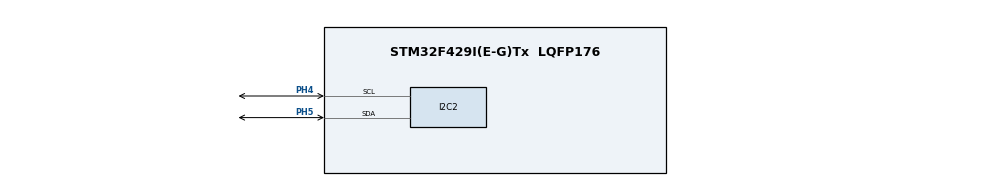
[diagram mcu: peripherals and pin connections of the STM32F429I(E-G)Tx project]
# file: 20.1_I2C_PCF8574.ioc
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I2C2.I2C_Mode=I2C_Fast
Mcu.Family=STM32F4
Mcu.Name=STM32F429I(E-G)Tx
Mcu.Package=LQFP176
NVIC.PriorityGroup=NVIC_PRIORITYGROUP_4
PA13.Mode=Trace_Asynchronous_SW
PA13.Signal=SYS_JTMS-SWDIO
PA14.Mode=Trace_Asynchronous_SW
PA14.Signal=SYS_JTCK-SWCLK
PB3.Mode=Trace_Asynchronous_SW
PB3.Signal=SYS_JTDO-SWO
PC14/OSC32_IN.Mode=LSE-External-Oscillator
PC14/OSC32_IN.Signal=RCC_OSC32_IN
PC15/OSC32_OUT.Mode=LSE-External-Oscillator
PC15/OSC32_OUT.Signal=RCC_OSC32_OUT
PH0/OSC_IN.Mode=HSE-External-Oscillator
PH0/OSC_IN.Signal=RCC_OSC_IN
PH1/OSC_OUT.Mode=HSE-External-Oscillator
PH1/OSC_OUT.Signal=RCC_OSC_OUT
PH4.Mode=I2C
PH4.Signal=I2C2_SCL
PH5.Mode=I2C
PH5.Signal=I2C2_SDA
ProjectManager.HeapSize=0x200
ProjectManager.StackSize=0x400
ProjectManager.TargetToolchain=STM32CubeIDE
RCC.48MHZClocksFreq_Value=90000000
RCC.AHBFreq_Value=180000000
RCC.APB1CLKDivider=RCC_HCLK_DIV4
RCC.APB1Freq_Value=45000000
RCC.APB1TimFreq_Value=90000000
RCC.APB2CLKDivider=RCC_HCLK_DIV2
RCC.APB2Freq_Value=90000000
RCC.APB2TimFreq_Value=180000000
RCC.CortexFreq_Value=180000000
RCC.HCLKFreq_Value=180000000
RCC.HSE_VALUE=25000000
RCC.HSI_VALUE=16000000
RCC.PLLM=15
RCC.PLLN=216
RCC.PLLSourceVirtual=RCC_PLLSOURCE_HSE
RCC.SYSCLKFreq_VALUE=180000000
RCC.SYSCLKSource=RCC_SYSCLKSOURCE_PLLCLK
RCC.VCOOutputFreq_Value=360000000
board=custom

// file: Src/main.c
/* USER CODE BEGIN Header */
/**
 ******************************************************************************
 * @file           : main.c
 * @brief          : Main program body
 ******************************************************************************
 * @attention
 *
 * <h2><center>&copy; Copyright (c) 2019 STMicroelectronics.
 * All rights reserved.</center></h2>
 *
 * This software component is licensed by ST under BSD 3-Clause license,
 * the "License"; You may not use this file except in compliance with the
 * License. You may obtain a copy of the License at:
 *                        opensource.org/licenses/BSD-3-Clause
 *
 ******************************************************************************
 */
/* USER CODE END Header */

#include "main.h"
#include "i2c.h"
#include "gpio.h"

/* USER CODE BEGIN Includes */
#include <stdio.h>
#include "PCF8574.h"
/* USER CODE END Includes */

/* USER CODE BEGIN PD */
#define EEPROM_ADDRESS		0X40
//#define EEPROM_ADDRESS		0xA0
/* USER CODE END PD */

/* USER CODE BEGIN PV */
uint8_t wirte_singnal = 99;
uint8_t read_singnal = 0;

uint8_t sinagl_buf = 0;
/* USER CODE END PV */

void SystemClock_Config (void);

int main (void)
{

    /* MCU Configuration--------------------------------------------------------*/

    /* Reset of all peripherals, Initializes the Flash interface and the Systick. */
    HAL_Init ();

    /* Configure the system clock */
    SystemClock_Config ();

    /* Initialize all configured peripherals */
    MX_GPIO_Init ();
    MX_I2C2_Init ();
    /* USER CODE BEGIN 2 */
    printf ("Start\r\n");
    while (PCF8574_Init ());
    printf ("Init done\r\n");

    int data = 0x5f;
    /* USER CODE END 2 */

    /* Infinite loop */
    /* USER CODE BEGIN WHILE */
    while (1)
    {
	PCF8574_Write_bit (EX_IO, 1);
	HAL_Delay (100);
	PCF8574_Write_bit (EX_IO, 0);
	HAL_Delay (100);
//	printf ("%d\r\n", PCF8574_Read_bit (EX_IO));
//	HAL_Delay(100);
	/* USER CODE END WHILE */

    }
}

void SystemClock_Config (void)
{
    RCC_OscInitTypeDef RCC_OscInitStruct = { 0 };
    RCC_ClkInitTypeDef RCC_ClkInitStruct = { 0 };

    /** Configure the main internal regulator output voltage
     */
    __HAL_RCC_PWR_CLK_ENABLE();
    __HAL_PWR_VOLTAGESCALING_CONFIG(PWR_REGULATOR_VOLTAGE_SCALE1);
    /** Initializes the CPU, AHB and APB busses clocks
     */
    RCC_OscInitStruct.OscillatorType = RCC_OSCILLATORTYPE_HSE;
    RCC_OscInitStruct.HSEState = RCC_HSE_ON;
    RCC_OscInitStruct.PLL.PLLState = RCC_PLL_ON;
    RCC_OscInitStruct.PLL.PLLSource = RCC_PLLSOURCE_HSE;
    RCC_OscInitStruct.PLL.PLLM = 15;
    RCC_OscInitStruct.PLL.PLLN = 216;
    RCC_OscInitStruct.PLL.PLLP = RCC_PLLP_DIV2;
    RCC_OscInitStruct.PLL.PLLQ = 4;
    if (HAL_RCC_OscConfig (&RCC_OscInitStruct) != HAL_OK)
    {
	Error_Handler ();
    }
    /** Activate the Over-Drive mode
     */
    if (HAL_PWREx_EnableOverDrive () != HAL_OK)
    {
	Error_Handler ();
    }
    /** Initializes the CPU, AHB and APB busses clocks
     */
    RCC_ClkInitStruct.ClockType = RCC_CLOCKTYPE_HCLK | RCC_CLOCKTYPE_SYSCLK | RCC_CLOCKTYPE_PCLK1 | RCC_CLOCKTYPE_PCLK2;
    RCC_ClkInitStruct.SYSCLKSource = RCC_SYSCLKSOURCE_PLLCLK;
    RCC_ClkInitStruct.AHBCLKDivider = RCC_SYSCLK_DIV1;
    RCC_ClkInitStruct.APB1CLKDivider = RCC_HCLK_DIV4;
    RCC_ClkInitStruct.APB2CLKDivider = RCC_HCLK_DIV2;

    if (HAL_RCC_ClockConfig (&RCC_ClkInitStruct, FLASH_LATENCY_5) != HAL_OK)
    {
	Error_Handler ();
    }
}

/* USER CODE BEGIN 4 */

int _write (int file,char*ptr,int len)
{
    int DataIdx;
    for (DataIdx = 0; DataIdx < len; DataIdx++)
    {
	ITM_SendChar (*ptr++);
    }
    return len;
}

/* USER CODE END 4 */

void Error_Handler (void)
{
}

/************************ (C) COPYRIGHT STMicroelectronics *****END OF FILE****/
